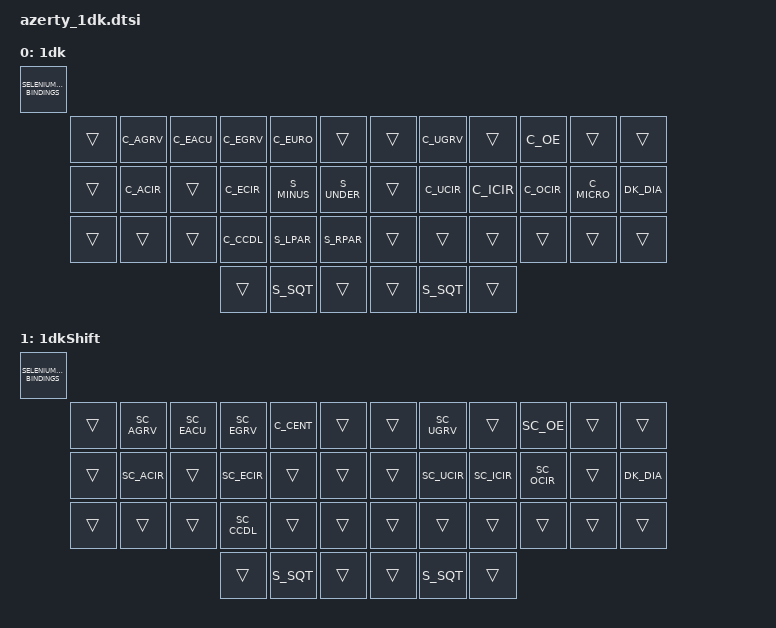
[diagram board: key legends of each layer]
#define ODK_LAYER        EXTRA_LAYERS_START_INDEX
#define ODK_SHIFT_LAYER (EXTRA_LAYERS_START_INDEX + 1)

// Override the standard base layer to replace SQT with a positional dead key.
&base_layer {
  bindings = <SELENIUM_KEYMAP_BINDINGS(
    K_LOUT1  ,  &kp Q &kp W &kp E &kp R &kp T  ,  &kp Y  &kp U  &kp I     &kp O   &kp P     ,  K_ROUT1 ,
    K_LOUT2  ,  &H4 A &H3 S &H2 D &H1 F &kp G  ,  &kp H  &H1 J  &H2 K     &H3 L   &H4 SEMI  ,  &dead_key  ,
    K_LOUT3  ,  &kp Z &kp X &kp C &kp V &kp B  ,  &kp N  &kp M  &kp COMMA &kp DOT &kp FSLH  ,  K_ROUT3 ,
     LTHUMB_TUCK , LTHUMB_HOME , LTHUMB_REACH  ,  RTHUMB_REACH , RTHUMB_HOME , RTHUMB_TUCK
  )>;
};

/ {
  behaviors {
    THREE_LEVEL_KEY(dead_key, &EZ_SL(ODK_LAYER), S_PRCNT, &EZ_SL(ODK_SHIFT_LAYER)) // ' % (1dk)
  };

  // Extra layers defined specifically for this keymap, appended to the base keymap.
  keymap {
    compatible = "zmk,keymap";

    one_dead_key {
      display-name = "1dk";
      bindings = <SELENIUM_KEYMAP_BINDINGS(
        &trans  ,  C_AGRV  C_EACU  C_EGRV  C_EURO  &trans   ,  &trans  C_UGRV  &trans  C_OE    &trans  ,  &trans ,
        &trans  ,  C_ACIR  &trans  C_ECIR  S_MINUS S_UNDER  ,  &trans  C_UCIR  C_ICIR  C_OCIR  C_MICRO ,  DK_DIA ,
        &trans  ,  &trans  &trans  C_CCDL  S_LPAR  S_RPAR   ,  &trans  &trans  &trans  &trans  &trans  ,  &trans ,
                                  &trans , S_SQT , &trans   ,  &trans , S_SQT , &trans
      )>;
    };

    one_dead_key_shift {
      display-name = "1dkShift";
      bindings = <SELENIUM_KEYMAP_BINDINGS(
        &trans  ,  SC_AGRV  SC_EACU  SC_EGRV  C_CENT   &trans   ,  &trans  SC_UGRV  &trans   SC_OE    &trans  ,  &trans ,
        &trans  ,  SC_ACIR  &trans   SC_ECIR  &trans   &trans   ,  &trans  SC_UCIR  SC_ICIR  SC_OCIR  &trans  ,  DK_DIA ,
        &trans  ,  &trans   &trans   SC_CCDL  &trans   &trans   ,  &trans  &trans   &trans   &trans   &trans  ,  &trans ,
                                      &trans , S_SQT , &trans   ,  &trans , S_SQT , &trans
      )>;
    };
  };
};
